# R7FA8D1BH register map
Vendor: Renesas; Series: RA8; File version: 1.2
CPU: CM85 r0p0, little endian, MPU, FPU, VTOR, 4 interrupt priority bits
Registers are 32-bit, read-write, reset 0x0 unless marked. A register's access mark holds for its fields unless they carry their own. Offsets are from the block's base; [hi:lo] are bit positions; {n}, {i} and the like mark numbered series; 'fields as' and 'values as' point back to an identical list.

## DSILINK (part 4 of 4)
Base 0x40346000
Same registers: DSILINK_NS 0x50346000
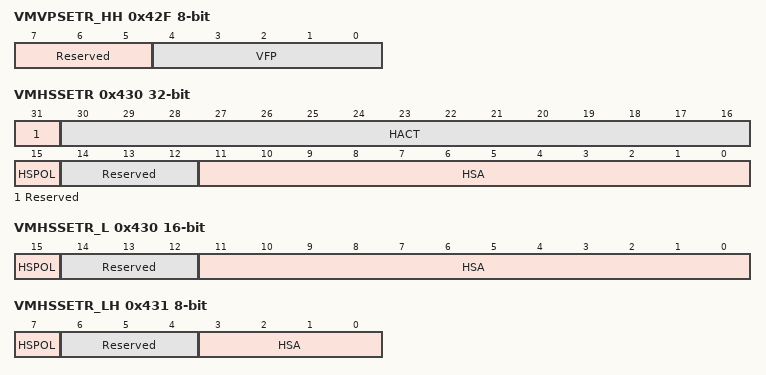
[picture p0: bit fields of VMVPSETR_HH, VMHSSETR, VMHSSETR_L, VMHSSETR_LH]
0x42F VMVPSETR_HH 8-bit (alternate view of VMVPSETR) — Video Mode Vertical Porch Set Register
  [7:5] Reserved — These bits are read as 000. The write value should be 000.
  [4:0] VFP — VFP Lines
0x430 VMHSSETR — Video Mode Horizontal Size Set Register
  [31] Reserved — This bit is read as 0. The write value should be 0.
  [30:16] HACT — HACT Pixels
  [15] HSPOL — HSYNC Polarity
    0=High Active; 1=Low Active
  [14:12] Reserved — These bits are read as 000. The write value should be 000.
  [11:0] HSA — HSA Pixels
0x430 VMHSSETR_L 16-bit (alternate view of VMHSSETR) — Video Mode Horizontal Size Set Register
  [15] HSPOL — HSYNC Polarity
    0=High Active; 1=Low Active
  [14:12] Reserved — These bits are read as 000. The write value should be 000.
  [11:0] HSA — HSA Pixels
0x430 VMHSSETR_LL 8-bit (alternate view of VMHSSETR) — Video Mode Horizontal Size Set Register
  [7:0] HSA — HSA Pixels
0x431 VMHSSETR_LH 8-bit (alternate view of VMHSSETR) — Video Mode Horizontal Size Set Register
  [7] HSPOL — HSYNC Polarity
    0=High Active; 1=Low Active
  [6:4] Reserved — These bits are read as 000. The write value should be 000.
  [3:0] HSA — HSA Pixels
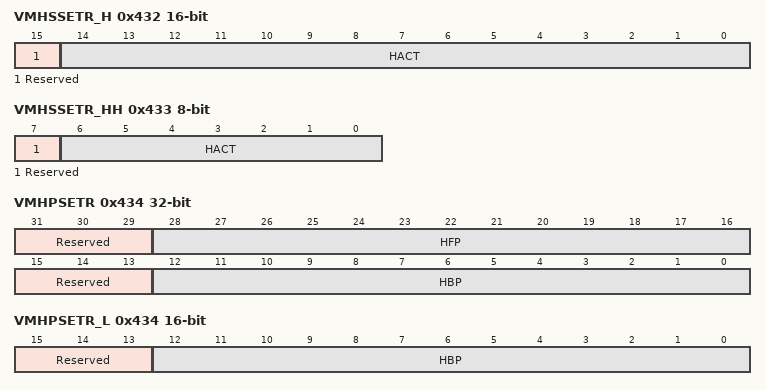
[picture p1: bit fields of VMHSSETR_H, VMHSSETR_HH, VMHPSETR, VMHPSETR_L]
0x432 VMHSSETR_H 16-bit (alternate view of VMHSSETR) — Video Mode Horizontal Size Set Register
  [15] Reserved — This bit is read as 0. The write value should be 0.
  [14:0] HACT — HACT Pixels
0x432 VMHSSETR_HL 8-bit (alternate view of VMHSSETR) — Video Mode Horizontal Size Set Register
  [7:0] HACT — HACT Pixels
0x433 VMHSSETR_HH 8-bit (alternate view of VMHSSETR) — Video Mode Horizontal Size Set Register
  [7] Reserved — This bit is read as 0. The write value should be 0.
  [6:0] HACT — HACT Pixels
0x434 VMHPSETR — Video Mode Horizontal Porch Set Register
  [31:29] Reserved — These bits are read as 000. The write value should be 000.
  [28:16] HFP — HFP Pixels
  [15:13] Reserved — These bits are read as 000. The write value should be 000.
  [12:0] HBP — HBP Pixels
0x434 VMHPSETR_L 16-bit (alternate view of VMHPSETR) — Video Mode Horizontal Porch Set Register
  [15:13] Reserved — These bits are read as 000. The write value should be 000.
  [12:0] HBP — HBP Pixels
0x434 VMHPSETR_LL 8-bit (alternate view of VMHPSETR) — Video Mode Horizontal Porch Set Register
  [7:0] HBP — HBP Pixels
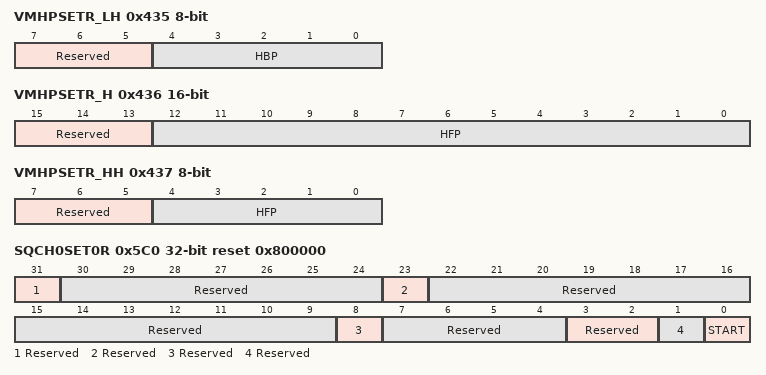
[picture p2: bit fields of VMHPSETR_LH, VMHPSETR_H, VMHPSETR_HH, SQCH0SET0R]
0x435 VMHPSETR_LH 8-bit (alternate view of VMHPSETR) — Video Mode Horizontal Porch Set Register
  [7:5] Reserved — These bits are read as 000. The write value should be 000.
  [4:0] HBP — HBP Pixels
0x436 VMHPSETR_H 16-bit (alternate view of VMHPSETR) — Video Mode Horizontal Porch Set Register
  [15:13] Reserved — These bits are read as 000. The write value should be 000.
  [12:0] HFP — HFP Pixels
0x436 VMHPSETR_HL 8-bit (alternate view of VMHPSETR) — Video Mode Horizontal Porch Set Register
  [7:0] HFP — HFP Pixels
0x437 VMHPSETR_HH 8-bit (alternate view of VMHPSETR) — Video Mode Horizontal Porch Set Register
  [7:5] Reserved — These bits are read as 000. The write value should be 000.
  [4:0] HFP — HFP Pixels
0x5C0 SQCH0SET0R reset 0x800000 — Sequence Channel 0 Set 0 Register
  [31] Reserved — This bit is read as 0. The write value should be 0.
  [30:24] Reserved — These bits are read as 0000000. The write value should be 0000000.
  [23] Reserved — This bit is read as 1. The write value should be 1.
  [22:9] Reserved — These bits are read as 00000000000000. The write value should be 00000000000000.
  [8] Reserved — This bit is read as 0. The write value should be 0.
  [7:4] Reserved — These bits are read as 0000. The write value should be 0000.
  [3:2] Reserved — These bits are read as 00. The write value should be 00.
  [1] Reserved — This bit is read as 0. The write value should be 0.
  [0] START wo — Sequence Operation Start
    0=No operation; 1=Start the sequence operation
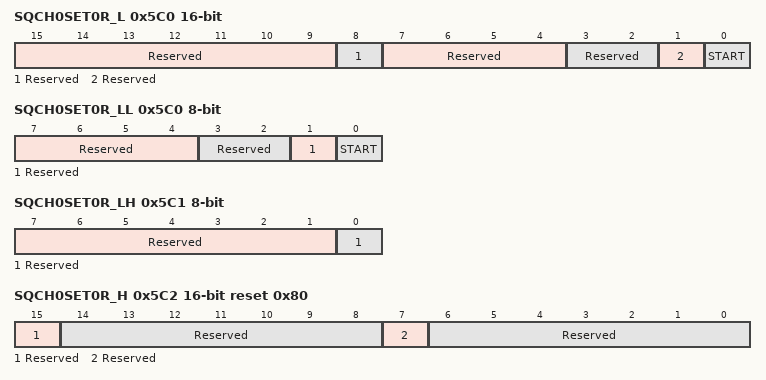
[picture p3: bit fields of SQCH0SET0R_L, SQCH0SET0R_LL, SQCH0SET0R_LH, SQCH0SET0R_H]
0x5C0 SQCH0SET0R_L 16-bit (alternate view of SQCH0SET0R) — Sequence Channel 0 Set 0 Register
  [15:9] Reserved — These bits are read as 0000000. The write value should be 0000000.
  [8] Reserved — This bit is read as 0. The write value should be 0.
  [7:4] Reserved — These bits are read as 0000. The write value should be 0000.
  [3:2] Reserved — These bits are read as 00. The write value should be 00.
  [1] Reserved — This bit is read as 0. The write value should be 0.
  [0] START wo — Sequence Operation Start
    0=No operation; 1=Start the sequence operation
0x5C0 SQCH0SET0R_LL 8-bit (alternate view of SQCH0SET0R) — Sequence Channel 0 Set 0 Register
  [7:4] Reserved — These bits are read as 0000. The write value should be 0000.
  [3:2] Reserved — These bits are read as 00. The write value should be 00.
  [1] Reserved — This bit is read as 0. The write value should be 0.
  [0] START wo — Sequence Operation Start
    0=No operation; 1=Start the sequence operation
0x5C1 SQCH0SET0R_LH 8-bit (alternate view of SQCH0SET0R) — Sequence Channel 0 Set 0 Register
  [7:1] Reserved — These bits are read as 0000000. The write value should be 0000000.
  [0] Reserved — This bit is read as 0. The write value should be 0.
0x5C2 SQCH0SET0R_H 16-bit reset 0x80 (alternate view of SQCH0SET0R) — Sequence Channel 0 Set 0 Register
  [15] Reserved — This bit is read as 0. The write value should be 0.
  [14:8] Reserved — These bits are read as 0000000. The write value should be 0000000.
  [7] Reserved — This bit is read as 1. The write value should be 1.
  [6:0] Reserved — These bits are read as 0000000. The write value should be 0000000.
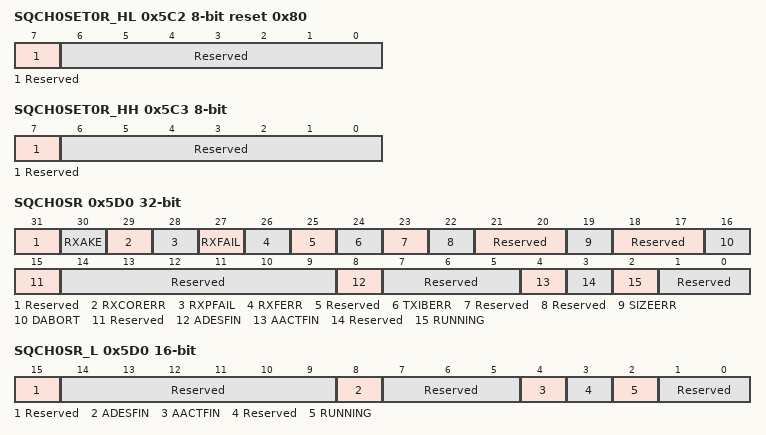
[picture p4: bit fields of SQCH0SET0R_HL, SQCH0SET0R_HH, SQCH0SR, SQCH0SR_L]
0x5C2 SQCH0SET0R_HL 8-bit reset 0x80 (alternate view of SQCH0SET0R) — Sequence Channel 0 Set 0 Register
  [7] Reserved — This bit is read as 1. The write value should be 1.
  [6:0] Reserved — These bits are read as 0000000. The write value should be 0000000.
0x5C3 SQCH0SET0R_HH 8-bit wo (alternate view of SQCH0SET0R) — Sequence Channel 0 Set 0 Register
  [7] Reserved — The write value should be 0.
  [6:0] Reserved — The write value should be 0000000.
0x5D0 SQCH0SR ro — Sequence Channel 0 Status Register
  [31] Reserved — This bit is read as 0.
  [30] RXAKE — Receive Acknowledge and Error Report Packet Interrupt Flag
    0=No error; 1=Acknowledge and Error Report Packet is received
  [29] RXCORERR — Receive Correctable Error Interrupt Flag
    0=No error; 1=Received packets have correctable error
  [28] RXPFAIL — Receive Packet Data Fail Interrupt Flag
    0=No error; 1=Received packet data is not stored correctly
  [27] RXFAIL — Receive Fail Interrupt Flag
    0=No error; 1=Expected receive did not take place
  [26] RXFERR — Receive Fatal Error Interrupt Flag
    0=No error; 1=Fatal timeout occurred during BTA
  [25] Reserved — This bit is read as 0.
  [24] TXIBERR — Tx Internal Bus Error Interrupt Flag
    0=No error; 1=Internal AXI bus read error occurred
  [23] Reserved — This bit is read as 0.
  [22] Reserved — This bit is read as 0.
  [21:20] Reserved — These bits are read as 00.
  [19] SIZEERR — Packet Size Error Interrupt Flag
    0=No error; 1=Sequence packet size is too large
  [18:17] Reserved — These bits are read as 00.
  [16] DABORT — Descriptor Abort Interrupt Flag
    0=No aborted descriptor; 1=A descriptor execution was aborted
  [15] Reserved — This bit is read as 0.
  [14:9] Reserved — These bits are read as 000000.
  [8] ADESFIN — All-Descriptors Finish Interrupt Flag
    0=All descriptors have not finished; 1=All descriptors finished operations
  [7:5] Reserved — These bits are read as 000.
  [4] AACTFIN — All Actions Finish Interrupt Flag
    0=All actions of a descriptor have not finished; 1=All actions of a descriptor finished operations
  [3] Reserved — This bit is read as 0.
  [2] RUNNING — Sequence Operation Running Status
    0=Sequence operation is stopped; 1=Sequence operation is running
  [1:0] Reserved — These bits are read as 00.
0x5D0 SQCH0SR_L 16-bit ro (alternate view of SQCH0SR) — Sequence Channel 0 Status Register
  [15] Reserved — This bit is read as 0.
  [14:9] Reserved — These bits are read as 000000.
  [8] ADESFIN — All-Descriptors Finish Interrupt Flag
    values as SQCH0SR.ADESFIN
  [7:5] Reserved — These bits are read as 000.
  [4] AACTFIN — All Actions Finish Interrupt Flag
    values as SQCH0SR.AACTFIN
  [3] Reserved — This bit is read as 0.
  [2] RUNNING — Sequence Operation Running Status
    values as SQCH0SR.RUNNING
  [1:0] Reserved — These bits are read as 00.
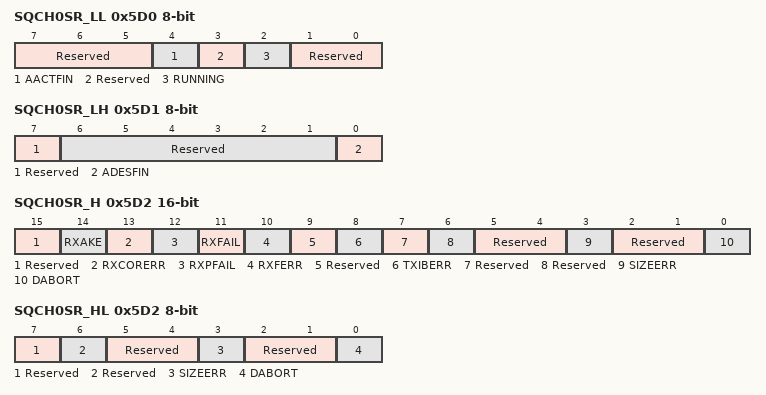
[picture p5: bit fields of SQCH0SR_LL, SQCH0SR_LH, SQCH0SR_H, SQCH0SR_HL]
0x5D0 SQCH0SR_LL 8-bit ro (alternate view of SQCH0SR) — Sequence Channel 0 Status Register
  [7:5] Reserved — These bits are read as 000.
  [4] AACTFIN — All Actions Finish Interrupt Flag
    values as SQCH0SR.AACTFIN
  [3] Reserved — This bit is read as 0.
  [2] RUNNING — Sequence Operation Running Status
    values as SQCH0SR.RUNNING
  [1:0] Reserved — These bits are read as 00.
0x5D1 SQCH0SR_LH 8-bit ro (alternate view of SQCH0SR) — Sequence Channel 0 Status Register
  [7] Reserved — This bit is read as 0.
  [6:1] Reserved — These bits are read as 000000.
  [0] ADESFIN — All-Descriptors Finish Interrupt Flag
    values as SQCH0SR.ADESFIN
0x5D2 SQCH0SR_H 16-bit ro (alternate view of SQCH0SR) — Sequence Channel 0 Status Register
  [15] Reserved — This bit is read as 0.
  [14] RXAKE — Receive Acknowledge and Error Report Packet Interrupt Flag
    values as SQCH0SR.RXAKE
  [13] RXCORERR — Receive Correctable Error Interrupt Flag
    0=No error; 1=Received packets have correctable error
  [12] RXPFAIL — Receive Packet Data Fail Interrupt Flag
    0=No error; 1=Received packet data is not stored correctly
  [11] RXFAIL — Receive Fail Interrupt Flag
    0=No error; 1=Expected receive did not take place
  [10] RXFERR — Receive Fatal Error Interrupt Flag
    0=No error; 1=Fatal timeout occurred during BTA
  [9] Reserved — This bit is read as 0.
  [8] TXIBERR — Tx Internal Bus Error Interrupt Flag
    0=No error; 1=Internal AXI bus read error occurred
  [7] Reserved — This bit is read as 0.
  [6] Reserved — This bit is read as 0.
  [5:4] Reserved — These bits are read as 00.
  [3] SIZEERR — Packet Size Error Interrupt Flag
    0=No error; 1=Sequence packet size is too large
  [2:1] Reserved — These bits are read as 00.
  [0] DABORT — Descriptor Abort Interrupt Flag
    values as SQCH0SR.DABORT
0x5D2 SQCH0SR_HL 8-bit ro (alternate view of SQCH0SR) — Sequence Channel 0 Status Register
  [7] Reserved — This bit is read as 0.
  [6] Reserved — This bit is read as 0.
  [5:4] Reserved — These bits are read as 00.
  [3] SIZEERR — Packet Size Error Interrupt Flag
    0=No error; 1=Sequence packet size is too large
  [2:1] Reserved — These bits are read as 00.
  [0] DABORT — Descriptor Abort Interrupt Flag
    values as SQCH0SR.DABORT
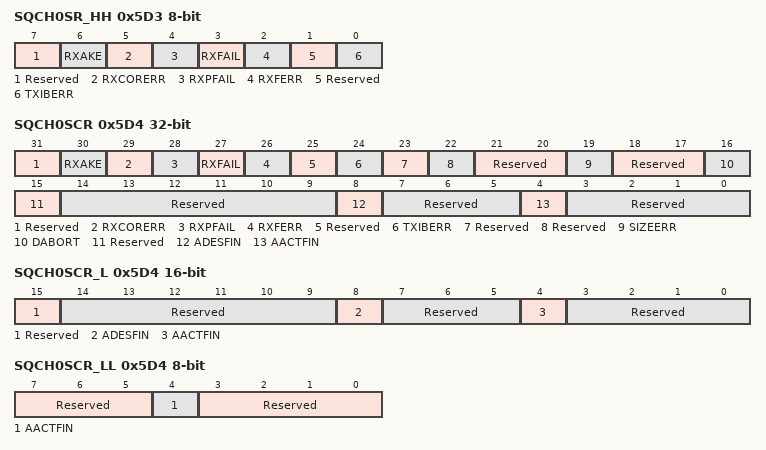
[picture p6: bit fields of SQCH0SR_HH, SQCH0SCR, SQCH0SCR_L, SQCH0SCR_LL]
0x5D3 SQCH0SR_HH 8-bit ro (alternate view of SQCH0SR) — Sequence Channel 0 Status Register
  [7] Reserved — This bit is read as 0.
  [6] RXAKE — Receive Acknowledge and Error Report Packet Interrupt Flag
    values as SQCH0SR.RXAKE
  [5] RXCORERR — Receive Correctable Error Interrupt Flag
    0=No error; 1=Received packets have correctable error
  [4] RXPFAIL — Receive Packet Data Fail Interrupt Flag
    0=No error; 1=Received packet data is not stored correctly
  [3] RXFAIL — Receive Fail Interrupt Flag
    0=No error; 1=Expected receive did not take place
  [2] RXFERR — Receive Fatal Error Interrupt Flag
    0=No error; 1=Fatal timeout occurred during BTA
  [1] Reserved — This bit is read as 0.
  [0] TXIBERR — Tx Internal Bus Error Interrupt Flag
    0=No error; 1=Internal AXI bus read error occurred
0x5D4 SQCH0SCR — Sequence Channel 0 Status Clear Register
  [31] Reserved — This bit is read as 0. The write value should be 0.
  [30] RXAKE write-1-clears read-modifies — Receive Acknowledge and Error Report Packet Interrupt Flag Clear
    0=No operation; 1=Clear the SQCHnSR.RXAKE flag
  [29] RXCORERR write-1-clears read-modifies — Receive Correctable Error Interrupt Flag Clear
    0=No operation; 1=Clear the SQCHnSR.RXCORERR flag
  [28] RXPFAIL write-1-clears read-modifies — Receive Packet Data Fail Interrupt Flag Clear
    0=No operation; 1=Clear the SQCHnSR.RXPFAIL flag
  [27] RXFAIL write-1-clears read-modifies — Receive Fail Interrupt Flag Clear
    0=No operation; 1=Clear the SQCHnSR.RXFAIL flag
  [26] RXFERR write-1-clears read-modifies — Receive Fatal Error Interrupt Flag Clear
    0=No operation; 1=Clear the SQCHnSR.RXFERR flag
  [25] Reserved — This bit is read as 0. The write value should be 0.
  [24] TXIBERR write-1-clears read-modifies — Tx Internal Bus Error Interrupt Flag Clear
    0=No operation; 1=Clear the SQCHnSR.TXIBERR flag
  [23] Reserved — This bit is read as 0. The write value should be 0.
  [22] Reserved — This bit is read as 0. The write value should be 0.
  [21:20] Reserved — These bits are read as 00. The write value should be 00.
  [19] SIZEERR — Packet Size Error Interrupt Flag Clear
    0=No operation; 1=Clear the SQCHnSR.SIZEERR flag
  [18:17] Reserved — These bits are read as 00. The write value should be 00.
  [16] DABORT write-1-clears read-modifies — Descriptor Abort Interrupt Flag Clear
    0=No operation; 1=Clear the SQCHnSR.DABORT flag
  [15] Reserved — This bit is read as 0. The write value should be 0.
  [14:9] Reserved — These bits are read as 000000. The write value should be 000000.
  [8] ADESFIN write-1-clears read-modifies — All-Descriptors Finish Interrupt Flag Clear
    0=No operation; 1=Clear the SQCHnSR.ADESFIN flag
  [7:5] Reserved — These bits are read as 000. The write value should be 000.
  [4] AACTFIN write-1-clears read-modifies — All Actions Finish Interrupt Flag Clear
    0=No operation; 1=Clear the SQCHnSR.AACTFIN flag
  [3:0] Reserved — These bits are read as 0000. The write value should be 0000.
0x5D4 SQCH0SCR_L 16-bit (alternate view of SQCH0SCR) — Sequence Channel 0 Status Clear Register
  [15] Reserved — This bit is read as 0. The write value should be 0.
  [14:9] Reserved — These bits are read as 000000. The write value should be 000000.
  [8] ADESFIN write-1-clears read-modifies — All-Descriptors Finish Interrupt Flag Clear
    0=No operation; 1=Clear the SQCHnSR.ADESFIN flag
  [7:5] Reserved — These bits are read as 000. The write value should be 000.
  [4] AACTFIN write-1-clears read-modifies — All Actions Finish Interrupt Flag Clear
    0=No operation; 1=Clear the SQCHnSR.AACTFIN flag
  [3:0] Reserved — These bits are read as 0000. The write value should be 0000.
0x5D4 SQCH0SCR_LL 8-bit (alternate view of SQCH0SCR) — Sequence Channel 0 Status Clear Register
  [7:5] Reserved — These bits are read as 000. The write value should be 000.
  [4] AACTFIN write-1-clears read-modifies — All Actions Finish Interrupt Flag Clear
    0=No operation; 1=Clear the SQCHnSR.AACTFIN flag
  [3:0] Reserved — These bits are read as 0000. The write value should be 0000.
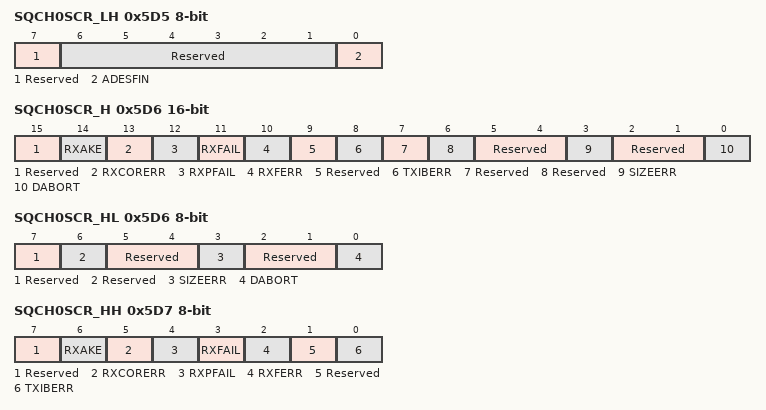
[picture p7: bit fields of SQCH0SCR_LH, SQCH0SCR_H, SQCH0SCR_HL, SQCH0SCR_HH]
0x5D5 SQCH0SCR_LH 8-bit (alternate view of SQCH0SCR) — Sequence Channel 0 Status Clear Register
  [7] Reserved — This bit is read as 0. The write value should be 0.
  [6:1] Reserved — These bits are read as 000000. The write value should be 000000.
  [0] ADESFIN write-1-clears read-modifies — All-Descriptors Finish Interrupt Flag Clear
    0=No operation; 1=Clear the SQCHnSR.ADESFIN flag
0x5D6 SQCH0SCR_H 16-bit (alternate view of SQCH0SCR) — Sequence Channel 0 Status Clear Register
  [15] Reserved — This bit is read as 0. The write value should be 0.
  [14] RXAKE write-1-clears read-modifies — Receive Acknowledge and Error Report Packet Interrupt Flag Clear
    0=No operation; 1=Clear the SQCHnSR.RXAKE flag
  [13] RXCORERR write-1-clears read-modifies — Receive Correctable Error Interrupt Flag Clear
    0=No operation; 1=Clear the SQCHnSR.RXCORERR flag
  [12] RXPFAIL write-1-clears read-modifies — Receive Packet Data Fail Interrupt Flag Clear
    0=No operation; 1=Clear the SQCHnSR.RXPFAIL flag
  [11] RXFAIL write-1-clears read-modifies — Receive Fail Interrupt Flag Clear
    0=No operation; 1=Clear the SQCHnSR.RXFAIL flag
  [10] RXFERR write-1-clears read-modifies — Receive Fatal Error Interrupt Flag Clear
    0=No operation; 1=Clear the SQCHnSR.RXFERR flag
  [9] Reserved — This bit is read as 0. The write value should be 0.
  [8] TXIBERR write-1-clears read-modifies — Tx Internal Bus Error Interrupt Flag Clear
    0=No operation; 1=Clear the SQCHnSR.TXIBERR flag
  [7] Reserved — This bit is read as 0. The write value should be 0.
  [6] Reserved — This bit is read as 0. The write value should be 0.
  [5:4] Reserved — These bits are read as 00. The write value should be 00.
  [3] SIZEERR — Packet Size Error Interrupt Flag Clear
    0=No operation; 1=Clear the SQCHnSR.SIZEERR flag
  [2:1] Reserved — These bits are read as 00. The write value should be 00.
  [0] DABORT write-1-clears read-modifies — Descriptor Abort Interrupt Flag Clear
    0=No operation; 1=Clear the SQCHnSR.DABORT flag
0x5D6 SQCH0SCR_HL 8-bit (alternate view of SQCH0SCR) — Sequence Channel 0 Status Clear Register
  [7] Reserved — This bit is read as 0. The write value should be 0.
  [6] Reserved — This bit is read as 0. The write value should be 0.
  [5:4] Reserved — These bits are read as 00. The write value should be 00.
  [3] SIZEERR — Packet Size Error Interrupt Flag Clear
    0=No operation; 1=Clear the SQCHnSR.SIZEERR flag
  [2:1] Reserved — These bits are read as 00. The write value should be 00.
  [0] DABORT write-1-clears read-modifies — Descriptor Abort Interrupt Flag Clear
    0=No operation; 1=Clear the SQCHnSR.DABORT flag
0x5D7 SQCH0SCR_HH 8-bit (alternate view of SQCH0SCR) — Sequence Channel 0 Status Clear Register
  [7] Reserved — This bit is read as 0. The write value should be 0.
  [6] RXAKE write-1-clears read-modifies — Receive Acknowledge and Error Report Packet Interrupt Flag Clear
    0=No operation; 1=Clear the SQCHnSR.RXAKE flag
  [5] RXCORERR write-1-clears read-modifies — Receive Correctable Error Interrupt Flag Clear
    0=No operation; 1=Clear the SQCHnSR.RXCORERR flag
  [4] RXPFAIL write-1-clears read-modifies — Receive Packet Data Fail Interrupt Flag Clear
    0=No operation; 1=Clear the SQCHnSR.RXPFAIL flag
  [3] RXFAIL write-1-clears read-modifies — Receive Fail Interrupt Flag Clear
    0=No operation; 1=Clear the SQCHnSR.RXFAIL flag
  [2] RXFERR write-1-clears read-modifies — Receive Fatal Error Interrupt Flag Clear
    0=No operation; 1=Clear the SQCHnSR.RXFERR flag
  [1] Reserved — This bit is read as 0. The write value should be 0.
  [0] TXIBERR write-1-clears read-modifies — Tx Internal Bus Error Interrupt Flag Clear
    0=No operation; 1=Clear the SQCHnSR.TXIBERR flag
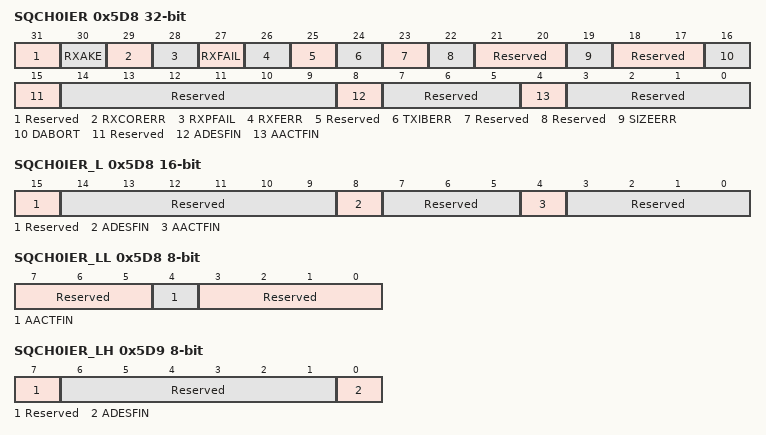
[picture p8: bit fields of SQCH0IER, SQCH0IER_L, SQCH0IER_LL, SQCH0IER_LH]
0x5D8 SQCH0IER — Sequence Channel 0 Interrupt Enable Register
  [31] Reserved — This bit is read as 0. The write value should be 0.
  [30] RXAKE — Receive Acknowledge and Error Report Packet Interrupt Enable
    0=Disable; 1=Enable
  [29] RXCORERR — Receive Correctable Error Interrupt Enable
    0=Disable; 1=Enable
  [28] RXPFAIL — Receive Packet Data Fail Interrupt Enable
    0=Disable; 1=Enable
  [27] RXFAIL — Receive Fail Interrupt Enable
    0=Disable; 1=Enable
  [26] RXFERR — Receive Fatal Error Interrupt Enable
    0=Disable; 1=Enable
  [25] Reserved — This bit is read as 0. The write value should be 0.
  [24] TXIBERR — Tx Internal Bus Error Interrupt Enable
    0=Disable; 1=Enable
  [23] Reserved — This bit is read as 0. The write value should be 0.
  [22] Reserved — This bit is read as 0. The write value should be 0.
  [21:20] Reserved — These bits are read as 00. The write value should be 00.
  [19] SIZEERR — Packet Size Error Interrupt Enable
    0=Disable; 1=Enable
  [18:17] Reserved — These bits are read as 00. The write value should be 00.
  [16] DABORT — Descriptor Abort Interrupt Enable
    0=Disable; 1=Enable
  [15] Reserved — This bit is read as 0. The write value should be 0.
  [14:9] Reserved — These bits are read as 000000. The write value should be 000000.
  [8] ADESFIN — All-Descriptors Finish Interrupt Enable
    0=Disable; 1=Enable
  [7:5] Reserved — These bits are read as 000. The write value should be 000.
  [4] AACTFIN — All Actions Finish Interrupt Enable
    0=Disable; 1=Enable
  [3:0] Reserved — These bits are read as 0000. The write value should be 0000.
0x5D8 SQCH0IER_L 16-bit (alternate view of SQCH0IER) — Sequence Channel 0 Interrupt Enable Register
  [15] Reserved — This bit is read as 0. The write value should be 0.
  [14:9] Reserved — These bits are read as 000000. The write value should be 000000.
  [8] ADESFIN — All-Descriptors Finish Interrupt Enable
    0=Disable; 1=Enable
  [7:5] Reserved — These bits are read as 000. The write value should be 000.
  [4] AACTFIN — All Actions Finish Interrupt Enable
    0=Disable; 1=Enable
  [3:0] Reserved — These bits are read as 0000. The write value should be 0000.
0x5D8 SQCH0IER_LL 8-bit (alternate view of SQCH0IER) — Sequence Channel 0 Interrupt Enable Register
  [7:5] Reserved — These bits are read as 000. The write value should be 000.
  [4] AACTFIN — All Actions Finish Interrupt Enable
    0=Disable; 1=Enable
  [3:0] Reserved — These bits are read as 0000. The write value should be 0000.
0x5D9 SQCH0IER_LH 8-bit (alternate view of SQCH0IER) — Sequence Channel 0 Interrupt Enable Register
  [7] Reserved — This bit is read as 0. The write value should be 0.
  [6:1] Reserved — These bits are read as 000000. The write value should be 000000.
  [0] ADESFIN — All-Descriptors Finish Interrupt Enable
    0=Disable; 1=Enable
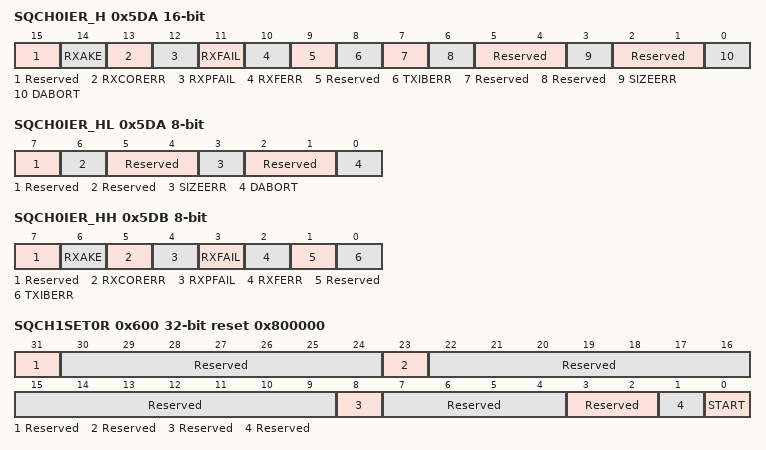
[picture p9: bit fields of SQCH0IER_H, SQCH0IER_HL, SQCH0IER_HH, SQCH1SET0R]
0x5DA SQCH0IER_H 16-bit (alternate view of SQCH0IER) — Sequence Channel 0 Interrupt Enable Register
  [15] Reserved — This bit is read as 0. The write value should be 0.
  [14] RXAKE — Receive Acknowledge and Error Report Packet Interrupt Enable
    0=Disable; 1=Enable
  [13] RXCORERR — Receive Correctable Error Interrupt Enable
    0=Disable; 1=Enable
  [12] RXPFAIL — Receive Packet Data Fail Interrupt Enable
    0=Disable; 1=Enable
  [11] RXFAIL — Receive Fail Interrupt Enable
    0=Disable; 1=Enable
  [10] RXFERR — Receive Fatal Error Interrupt Enable
    0=Disable; 1=Enable
  [9] Reserved — This bit is read as 0. The write value should be 0.
  [8] TXIBERR — Tx Internal Bus Error Interrupt Enable
    0=Disable; 1=Enable
  [7] Reserved — This bit is read as 0. The write value should be 0.
  [6] Reserved — This bit is read as 0. The write value should be 0.
  [5:4] Reserved — These bits are read as 00. The write value should be 00.
  [3] SIZEERR — Packet Size Error Interrupt Enable
    0=Disable; 1=Enable
  [2:1] Reserved — These bits are read as 00. The write value should be 00.
  [0] DABORT — Descriptor Abort Interrupt Enable
    0=Disable; 1=Enable
0x5DA SQCH0IER_HL 8-bit (alternate view of SQCH0IER) — Sequence Channel 0 Interrupt Enable Register
  [7] Reserved — This bit is read as 0. The write value should be 0.
  [6] Reserved — This bit is read as 0. The write value should be 0.
  [5:4] Reserved — These bits are read as 00. The write value should be 00.
  [3] SIZEERR — Packet Size Error Interrupt Enable
    0=Disable; 1=Enable
  [2:1] Reserved — These bits are read as 00. The write value should be 00.
  [0] DABORT — Descriptor Abort Interrupt Enable
    0=Disable; 1=Enable
0x5DB SQCH0IER_HH 8-bit (alternate view of SQCH0IER) — Sequence Channel 0 Interrupt Enable Register
  [7] Reserved — This bit is read as 0. The write value should be 0.
  [6] RXAKE — Receive Acknowledge and Error Report Packet Interrupt Enable
    0=Disable; 1=Enable
  [5] RXCORERR — Receive Correctable Error Interrupt Enable
    0=Disable; 1=Enable
  [4] RXPFAIL — Receive Packet Data Fail Interrupt Enable
    0=Disable; 1=Enable
  [3] RXFAIL — Receive Fail Interrupt Enable
    0=Disable; 1=Enable
  [2] RXFERR — Receive Fatal Error Interrupt Enable
    0=Disable; 1=Enable
  [1] Reserved — This bit is read as 0. The write value should be 0.
  [0] TXIBERR — Tx Internal Bus Error Interrupt Enable
    0=Disable; 1=Enable
0x600 SQCH1SET0R reset 0x800000 — Sequence Channel 1 Set 0 Register
  fields as SQCH0SET0R
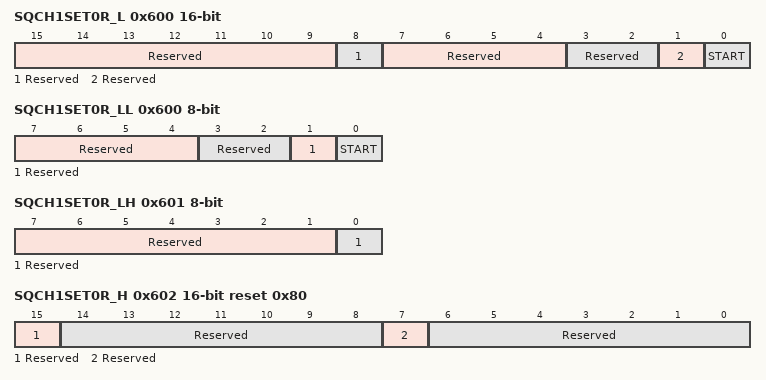
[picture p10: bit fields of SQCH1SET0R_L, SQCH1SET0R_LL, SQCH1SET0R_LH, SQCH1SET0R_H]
0x600 SQCH1SET0R_L 16-bit (alternate view of SQCH1SET0R) — Sequence Channel 1 Set 0 Register
  fields as SQCH0SET0R_L
0x600 SQCH1SET0R_LL 8-bit (alternate view of SQCH1SET0R) — Sequence Channel 1 Set 0 Register
  fields as SQCH0SET0R_LL
0x601 SQCH1SET0R_LH 8-bit (alternate view of SQCH1SET0R) — Sequence Channel 1 Set 0 Register
  fields as SQCH0SET0R_LH
0x602 SQCH1SET0R_H 16-bit reset 0x80 (alternate view of SQCH1SET0R) — Sequence Channel 1 Set 0 Register
  fields as SQCH0SET0R_H
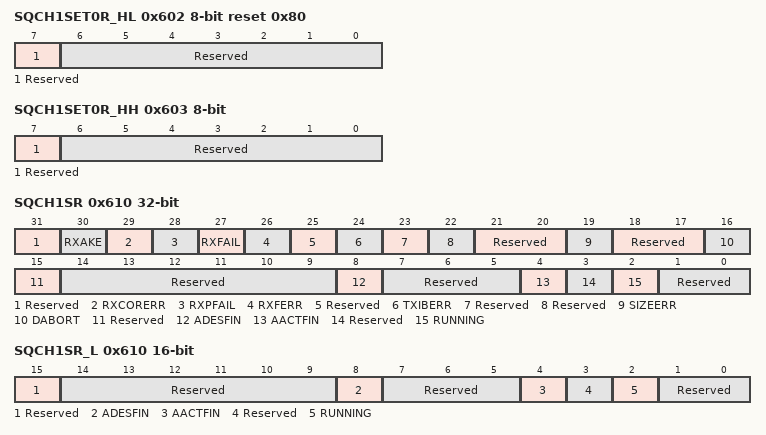
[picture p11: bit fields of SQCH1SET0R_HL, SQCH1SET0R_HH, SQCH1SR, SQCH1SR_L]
0x602 SQCH1SET0R_HL 8-bit reset 0x80 (alternate view of SQCH1SET0R) — Sequence Channel 1 Set 0 Register
  fields as SQCH0SET0R_HL
0x603 SQCH1SET0R_HH 8-bit wo (alternate view of SQCH1SET0R) — Sequence Channel 1 Set 0 Register
  fields as SQCH0SET0R_HH
0x610 SQCH1SR ro — Sequence Channel 1 Status Register
  fields as SQCH0SR
0x610 SQCH1SR_L 16-bit ro (alternate view of SQCH1SR) — Sequence Channel 1 Status Register
  fields as SQCH0SR_L
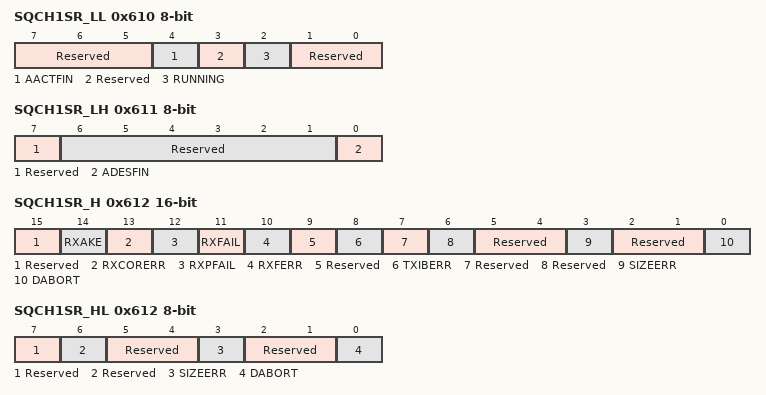
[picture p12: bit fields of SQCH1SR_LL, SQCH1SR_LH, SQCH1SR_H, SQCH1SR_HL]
0x610 SQCH1SR_LL 8-bit ro (alternate view of SQCH1SR) — Sequence Channel 1 Status Register
  fields as SQCH0SR_LL
0x611 SQCH1SR_LH 8-bit ro (alternate view of SQCH1SR) — Sequence Channel 1 Status Register
  fields as SQCH0SR_LH
0x612 SQCH1SR_H 16-bit ro (alternate view of SQCH1SR) — Sequence Channel 1 Status Register
  fields as SQCH0SR_H
0x612 SQCH1SR_HL 8-bit ro (alternate view of SQCH1SR) — Sequence Channel 1 Status Register
  fields as SQCH0SR_HL
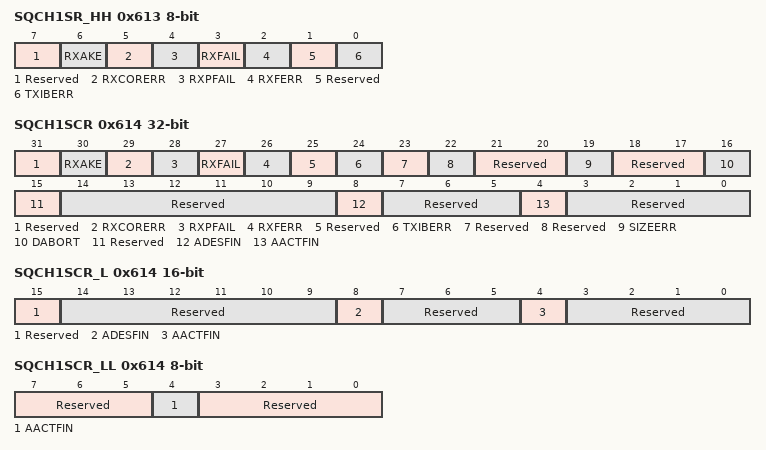
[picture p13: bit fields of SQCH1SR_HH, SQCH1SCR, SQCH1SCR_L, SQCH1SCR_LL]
0x613 SQCH1SR_HH 8-bit ro (alternate view of SQCH1SR) — Sequence Channel 1 Status Register
  fields as SQCH0SR_HH
0x614 SQCH1SCR — Sequence Channel 1 Status Clear Register
  fields as SQCH0SCR
0x614 SQCH1SCR_L 16-bit (alternate view of SQCH1SCR) — Sequence Channel 1 Status Clear Register
  fields as SQCH0SCR_L
0x614 SQCH1SCR_LL 8-bit (alternate view of SQCH1SCR) — Sequence Channel 1 Status Clear Register
  fields as SQCH0SCR_LL
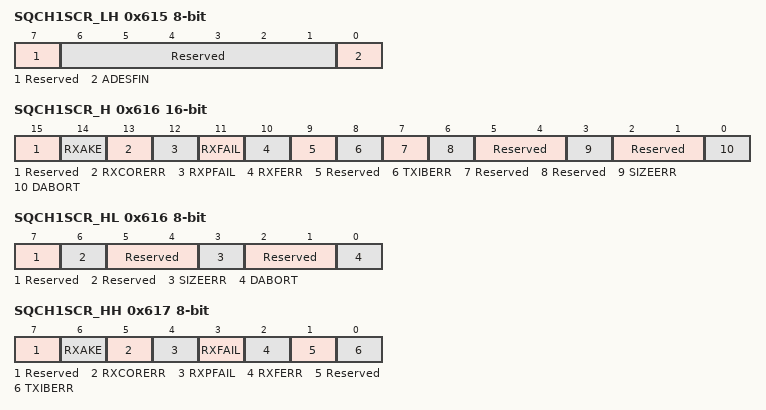
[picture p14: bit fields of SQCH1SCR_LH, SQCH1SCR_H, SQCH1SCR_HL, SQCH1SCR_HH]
0x615 SQCH1SCR_LH 8-bit (alternate view of SQCH1SCR) — Sequence Channel 1 Status Clear Register
  fields as SQCH0SCR_LH
0x616 SQCH1SCR_H 16-bit (alternate view of SQCH1SCR) — Sequence Channel 1 Status Clear Register
  fields as SQCH0SCR_H
0x616 SQCH1SCR_HL 8-bit (alternate view of SQCH1SCR) — Sequence Channel 1 Status Clear Register
  fields as SQCH0SCR_HL
0x617 SQCH1SCR_HH 8-bit (alternate view of SQCH1SCR) — Sequence Channel 1 Status Clear Register
  fields as SQCH0SCR_HH
0x618 SQCH1IER — Sequence Channel 1 Interrupt Enable Register
  fields as SQCH0IER
0x618 SQCH1IER_L 16-bit (alternate view of SQCH1IER) — Sequence Channel 1 Interrupt Enable Register
  fields as SQCH0IER_L
0x618 SQCH1IER_LL 8-bit (alternate view of SQCH1IER) — Sequence Channel 1 Interrupt Enable Register
  fields as SQCH0IER_LL
0x619 SQCH1IER_LH 8-bit (alternate view of SQCH1IER) — Sequence Channel 1 Interrupt Enable Register
  fields as SQCH0IER_LH
0x61A SQCH1IER_H 16-bit (alternate view of SQCH1IER) — Sequence Channel 1 Interrupt Enable Register
  fields as SQCH0IER_H
0x61A SQCH1IER_HL 8-bit (alternate view of SQCH1IER) — Sequence Channel 1 Interrupt Enable Register
  fields as SQCH0IER_HL
0x61B SQCH1IER_HH 8-bit (alternate view of SQCH1IER) — Sequence Channel 1 Interrupt Enable Register
  fields as SQCH0IER_HH
{0x780+0x10*i} SQCH0DSC{i}AR (i=0..7) reset not defined — Sequence Channel 0 Descriptor-{i} A Register
  [31:30] Reserved — These bits are read as 00. The write value should be 00.
  [29:28] NXACT — Next Action
    0=Terminate the sequence operation after this descriptor processing is finished; 1=Start the next descriptor processing after this descriptor processing is finished
  [27:26] BTA — Bus Turn Around
    0=Not assert BTA or No-operation; 1=Assert BTA; 2=Assert BTA followed by READ request (No WRITE request before BTA); 3=Assert BTA only (No WRITE request before BTA)
  [25] SPD — Speed
    0=High Speed; 1=Low Power
  [24] FMT — Format
    0=Short Packet; 1=Long Packet
  [23:22] VC — Virtual Channel
  [21:16] DT — Data Type
  [15:8] DATA1
  [7:0] DATA0
{0x780+0x10*i} SQCH0DSC{i}AR_L (i=0..7) 16-bit (alternate view of SQCH0DSC{i}AR) — Sequence Channel 0 Descriptor-{i} A Register
  [15:8] DATA1, [7:0] DATA0
{0x780+0x10*i} SQCH0DSC{i}AR_LL (i=0..7) 8-bit (alternate view of SQCH0DSC{i}AR) — Sequence Channel 0 Descriptor-{i} A Register
  [7:0] DATA0
{0x781+0x10*i} SQCH0DSC{i}AR_LH (i=0..7) 8-bit (alternate view of SQCH0DSC{i}AR) — Sequence Channel 0 Descriptor-{i} A Register
  [7:0] DATA1
{0x782+0x10*i} SQCH0DSC{i}AR_H (i=0..7) 16-bit (alternate view of SQCH0DSC{i}AR) — Sequence Channel 0 Descriptor-{i} A Register
  [15:14] Reserved — These bits are read as 00. The write value should be 00.
  [13:12] NXACT — Next Action
    values as SQCH0DSC0AR.NXACT
  [11:10] BTA — Bus Turn Around
    values as SQCH0DSC0AR.BTA
  [9] SPD — Speed
    0=High Speed; 1=Low Power
  [8] FMT — Format
    0=Short Packet; 1=Long Packet
  [7:6] VC — Virtual Channel
  [5:0] DT — Data Type
{0x782+0x10*i} SQCH0DSC{i}AR_HL (i=0..7) 8-bit (alternate view of SQCH0DSC{i}AR) — Sequence Channel 0 Descriptor-{i} A Register
  [7:6] VC — Virtual Channel
  [5:0] DT — Data Type
{0x783+0x10*i} SQCH0DSC{i}AR_HH (i=0..7) 8-bit (alternate view of SQCH0DSC{i}AR) — Sequence Channel 0 Descriptor-{i} A Register
  [7:6] Reserved — These bits are read as 00. The write value should be 00.
  [5:4] NXACT — Next Action
    values as SQCH0DSC0AR.NXACT
  [3:2] BTA — Bus Turn Around
    values as SQCH0DSC0AR.BTA
  [1] SPD — Speed
    0=High Speed; 1=Low Power
  [0] FMT — Format
    0=Short Packet; 1=Long Packet
{0x784+0x10*i} SQCH0DSC{i}BR (i=0..7) reset not defined — Sequence Channel 0 Descriptor-{i} B Register
  [31:26] Reserved — These bits are read as 000000. The write value should be 000000.
  [25:24] DTSEL — Data Select
    0=Use Packet Payload Data Register (TXPPDxR, RXPPDxR); 1=Use Sequence RAM
  [23] Reserved — This bit is read as 0. The write value should be 0.
  [22] Reserved — This bit is read as 0. The write value should be 0.
  [21:20] Reserved — These bits are read as 00. The write value should be 00.
  [19:16] Reserved — These bits are read as 0000. The write value should be 0000.
  [15:12] Reserved — These bits are read as 0000. The write value should be 0000.
  [11:0] Reserved — These bits are read as 000000000000. The write value should be 000000000000.
{0x788+0x10*i} SQCH0DSC{i}CR (i=0..7) reset not defined — Sequence Channel 0 Descriptor-{i} C Register
  [31:24] ACTCODE — Action Code
    {v}=Slot-{v} (RXRSS{v}R) (v=0..3); 0=Send Reset-Trigger; 4=Send Initial Skew calibration; 5=Send Periodic Skew calibration; 8=No-operation
  [23] Reserved — This bit is read as 0. The write value should be 0.
  [22] AUXOP — Auxiliary Operation
    0=Not use auxiliary operation; 1=Execute auxiliary operation
  [21:3] Reserved — These bits are read as 0000000000000000000. The write value should be 0000000000000000000.
  [2] Reserved — This bit is read as 0. The write value should be 0.
  [1] Reserved — This bit is read as 0. The write value should be 0.
  [0] FINACT — Finish Action
    0=Disable; 1=Enable
{0x788+0x10*i} SQCH0DSC{i}CR_L (i=0..7) 16-bit (alternate view of SQCH0DSC{i}CR) — Sequence Channel 0 Descriptor-{i} C Register
  [15:3] Reserved — These bits are read as 0000000000000. The write value should be 0000000000000.
  [2] Reserved — This bit is read as 0. The write value should be 0.
  [1] Reserved — This bit is read as 0. The write value should be 0.
  [0] FINACT — Finish Action
    0=Disable; 1=Enable
{0x788+0x10*i} SQCH0DSC{i}CR_LL (i=0..7) 8-bit (alternate view of SQCH0DSC{i}CR) — Sequence Channel 0 Descriptor-{i} C Register
  [7:3] Reserved — These bits are read as 00000. The write value should be 00000.
  [2] Reserved — This bit is read as 0. The write value should be 0.
  [1] Reserved — This bit is read as 0. The write value should be 0.
  [0] FINACT — Finish Action
    0=Disable; 1=Enable
{0x78A+0x10*i} SQCH0DSC{i}CR_H (i=0..7) 16-bit (alternate view of SQCH0DSC{i}CR) — Sequence Channel 0 Descriptor-{i} C Register
  [15:8] ACTCODE — Action Code
    values as SQCH0DSC0CR.ACTCODE
  [7] Reserved — This bit is read as 0. The write value should be 0.
  [6] AUXOP — Auxiliary Operation
    0=Not use auxiliary operation; 1=Execute auxiliary operation
  [5:0] Reserved — These bits are read as 000000. The write value should be 000000.
{0x78A+0x10*i} SQCH0DSC{i}CR_HL (i=0..7) 8-bit (alternate view of SQCH0DSC{i}CR) — Sequence Channel 0 Descriptor-{i} C Register
  [7] Reserved — This bit is read as 0. The write value should be 0.
  [6] AUXOP — Auxiliary Operation
    0=Not use auxiliary operation; 1=Execute auxiliary operation
  [5:0] Reserved — These bits are read as 000000. The write value should be 000000.
{0x78B+0x10*i} SQCH0DSC{i}CR_HH (i=0..7) 8-bit (alternate view of SQCH0DSC{i}CR) — Sequence Channel 0 Descriptor-{i} C Register
  [7:0] ACTCODE — Action Code
    values as SQCH0DSC0CR.ACTCODE
{0x78C+0x10*i} SQCH0DSC{i}DR (i=0..7) reset not defined — Sequence Channel 0 Descriptor-{i} D Register
  [31:0] LADDR — Lower Address
{0x78C+0x10*i} SQCH0DSC{i}DR_L (i=0..7) 16-bit (alternate view of SQCH0DSC{i}DR) — Sequence Channel 0 Descriptor-{i} D Register
  [15:0] LADDR — Lower Address
{0x78C+0x10*i} SQCH0DSC{i}DR_LL (i=0..7) 8-bit (alternate view of SQCH0DSC{i}DR) — Sequence Channel 0 Descriptor-{i} D Register
  [7:0] LADDR — Lower Address
{0x78D+0x10*i} SQCH0DSC{i}DR_LH (i=0..7) 8-bit (alternate view of SQCH0DSC{i}DR) — Sequence Channel 0 Descriptor-{i} D Register
  [7:0] LADDR — Lower Address
{0x78E+0x10*i} SQCH0DSC{i}DR_H (i=0..7) 16-bit (alternate view of SQCH0DSC{i}DR) — Sequence Channel 0 Descriptor-{i} D Register
  [15:0] LADDR — Lower Address
{0x78E+0x10*i} SQCH0DSC{i}DR_HL (i=0..7) 8-bit (alternate view of SQCH0DSC{i}DR) — Sequence Channel 0 Descriptor-{i} D Register
  [7:0] LADDR — Lower Address
{0x78F+0x10*i} SQCH0DSC{i}DR_HH (i=0..7) 8-bit (alternate view of SQCH0DSC{i}DR) — Sequence Channel 0 Descriptor-{i} D Register
  [7:0] LADDR — Lower Address
{0x800+0x10*i} SQCH1DSC{i}AR (i=0..7) reset not defined — Sequence Channel 1 Descriptor-{i} A Register
  fields as SQCH0DSC0AR
{0x800+0x10*i} SQCH1DSC{i}AR_L (i=0..7) 16-bit (alternate view of SQCH1DSC{i}AR) — Sequence Channel 1 Descriptor-{i} A Register
  [15:8] DATA1, [7:0] DATA0
{0x800+0x10*i} SQCH1DSC{i}AR_LL (i=0..7) 8-bit (alternate view of SQCH1DSC{i}AR) — Sequence Channel 1 Descriptor-{i} A Register
  [7:0] DATA0
{0x801+0x10*i} SQCH1DSC{i}AR_LH (i=0..7) 8-bit (alternate view of SQCH1DSC{i}AR) — Sequence Channel 1 Descriptor-{i} A Register
  [7:0] DATA1
{0x802+0x10*i} SQCH1DSC{i}AR_H (i=0..7) 16-bit (alternate view of SQCH1DSC{i}AR) — Sequence Channel 1 Descriptor-{i} A Register
  fields as SQCH0DSC0AR_H
{0x802+0x10*i} SQCH1DSC{i}AR_HL (i=0..7) 8-bit (alternate view of SQCH1DSC{i}AR) — Sequence Channel 1 Descriptor-{i} A Register
  [7:6] VC — Virtual Channel
  [5:0] DT — Data Type
{0x803+0x10*i} SQCH1DSC{i}AR_HH (i=0..7) 8-bit (alternate view of SQCH1DSC{i}AR) — Sequence Channel 1 Descriptor-{i} A Register
  fields as SQCH0DSC0AR_HH
{0x804+0x10*i} SQCH1DSC{i}BR (i=0..7) reset not defined — Sequence Channel 1 Descriptor-{i} B Register
  fields as SQCH0DSC0BR
{0x808+0x10*i} SQCH1DSC{i}CR (i=0..7) reset not defined — Sequence Channel 1 Descriptor-{i} C Register
  fields as SQCH0DSC0CR
{0x808+0x10*i} SQCH1DSC{i}CR_L (i=0..7) 16-bit (alternate view of SQCH1DSC{i}CR) — Sequence Channel 1 Descriptor-{i} C Register
  fields as SQCH0DSC0CR_L
{0x808+0x10*i} SQCH1DSC{i}CR_LL (i=0..7) 8-bit (alternate view of SQCH1DSC{i}CR) — Sequence Channel 1 Descriptor-{i} C Register
  fields as SQCH0DSC0CR_LL
{0x80A+0x10*i} SQCH1DSC{i}CR_H (i=0..7) 16-bit (alternate view of SQCH1DSC{i}CR) — Sequence Channel 1 Descriptor-{i} C Register
  fields as SQCH0DSC0CR_H
{0x80A+0x10*i} SQCH1DSC{i}CR_HL (i=0..7) 8-bit (alternate view of SQCH1DSC{i}CR) — Sequence Channel 1 Descriptor-{i} C Register
  fields as SQCH0DSC0CR_HL
{0x80B+0x10*i} SQCH1DSC{i}CR_HH (i=0..7) 8-bit (alternate view of SQCH1DSC{i}CR) — Sequence Channel 1 Descriptor-{i} C Register
  fields as SQCH0DSC0CR_HH
{0x80C+0x10*i} SQCH1DSC{i}DR (i=0..7) reset not defined — Sequence Channel 1 Descriptor-{i} D Register
  [31:0] LADDR — Lower Address
{0x80C+0x10*i} SQCH1DSC{i}DR_L (i=0..7) 16-bit (alternate view of SQCH1DSC{i}DR) — Sequence Channel 1 Descriptor-{i} D Register
  [15:0] LADDR — Lower Address
{0x80C+0x10*i} SQCH1DSC{i}DR_LL (i=0..7) 8-bit (alternate view of SQCH1DSC{i}DR) — Sequence Channel 1 Descriptor-{i} D Register
  [7:0] LADDR — Lower Address
{0x80D+0x10*i} SQCH1DSC{i}DR_LH (i=0..7) 8-bit (alternate view of SQCH1DSC{i}DR) — Sequence Channel 1 Descriptor-{i} D Register
  [7:0] LADDR — Lower Address
{0x80E+0x10*i} SQCH1DSCmDR_H[{i}] (i=0..7) 16-bit (alternate view of SQCH1DSC{i}DR) — Sequence Channel 1 Descriptor-{i} D Register
  [15:0] LADDR — Lower Address
{0x80E+0x10*i} SQCH1DSC{i}DR_HL (i=0..7) 8-bit (alternate view of SQCH1DSC{i}DR) — Sequence Channel 1 Descriptor-{i} D Register
  [7:0] LADDR — Lower Address
{0x80F+0x10*i} SQCH1DSC{i}DR_HH (i=0..7) 8-bit (alternate view of SQCH1DSC{i}DR) — Sequence Channel 1 Descriptor-{i} D Register
  [7:0] LADDR — Lower Address
